# rac_cfg register map
Vendor: Texas Instruments
Peripheral module from a debugger description file (folder Keystone2).
Registers are 32-bit, read-write, no defined reset value unless marked. A register's access mark holds for its fields unless they carry their own. Offsets are as the file gives them; lines under a group give offsets from that group; [hi:lo] are bit positions; {n}, {i} and the like mark numbered series; 'fields as' and 'values as' point back to an identical list; <NAME> marks a mode.

## RAC_3_CFG
0x00 fe_pid access not given
0x04 fe_ena
  [0] enable
0x08 fe_id_depth
  [3:0] ib_depth
0x0C fe_max
  [15:0] max_cycles
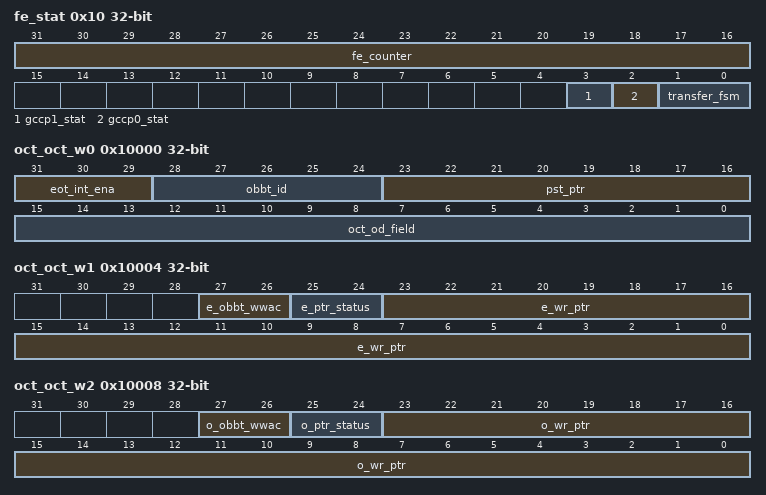
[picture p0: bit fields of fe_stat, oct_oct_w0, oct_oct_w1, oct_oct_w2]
0x10 fe_stat
  [31:16] fe_counter, [3] gccp1_stat, [2] gccp0_stat, [1:0] transfer_fsm
0x14 fe_wcfg
  [15:0] fe_wd_cfg
0x18 fe_wst
  [15:0] fe_wd_status
0x1C fe_int
  [0] int_status
0x20 fe_sw_reset
  [0] sw_reset
0x24 fe_sw_ite_start
  [0] ite_start
0x28 fe_time access not given
0x10000 oct_oct_w0 — (1 of 768, stride 16)
  [31:29] eot_int_ena, [28:24] obbt_id, [23:16] pst_ptr, [15:0] oct_od_field
0x10004 oct_oct_w1 — (1 of 768, stride 16)
  [27:26] e_obbt_wwac, [25:24] e_ptr_status, [23:0] e_wr_ptr
0x10008 oct_oct_w2 — (1 of 768, stride 16)
  [27:26] o_obbt_wwac, [25:24] o_ptr_status, [23:0] o_wr_ptr
0x13000 obbt_obbt_w0 — (1 of 32, stride 32)
  [31:0] start_ad
0x13004 obbt_obbt_w1 — (1 of 32, stride 32)
  [23:0] buff_size
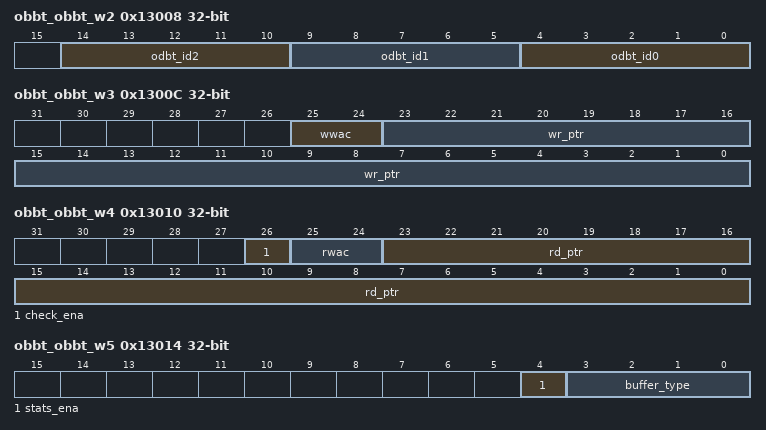
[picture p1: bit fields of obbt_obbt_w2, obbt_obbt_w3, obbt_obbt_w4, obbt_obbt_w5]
0x13008 obbt_obbt_w2 — (1 of 32, stride 32)
  [14:10] odbt_id2, [9:5] odbt_id1, [4:0] odbt_id0
0x1300C obbt_obbt_w3 — (1 of 32, stride 32)
  [25:24] wwac, [23:0] wr_ptr
0x13010 obbt_obbt_w4 — (1 of 32, stride 32)
  [26] check_ena, [25:24] rwac, [23:0] rd_ptr
0x13014 obbt_obbt_w5 — (1 of 32, stride 32)
  [4] stats_ena, [3:0] buffer_type
0x13400 odbt_odbt_w0 — (1 of 32, stride 16)
  [31:0] start_ad
0x13404 odbt_odbt_w1 — (1 of 32, stride 16)
  [15:0] buffer_size
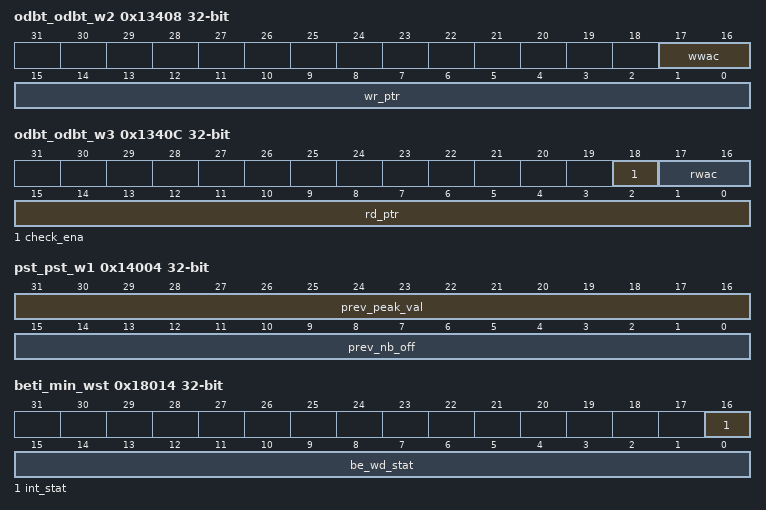
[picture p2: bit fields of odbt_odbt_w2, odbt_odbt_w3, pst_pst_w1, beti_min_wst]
0x13408 odbt_odbt_w2 — (1 of 32, stride 16)
  [17:16] wwac, [15:0] wr_ptr
0x1340C odbt_odbt_w3 — (1 of 32, stride 16)
  [18] check_ena, [17:16] rwac, [15:0] rd_ptr
0x14000 pst_pst_w0 — (1 of 256, stride 16)
  [31:0] prev_sum
0x14004 pst_pst_w1 — (1 of 256, stride 16)
  [31:16] prev_peak_val, [15:0] prev_nb_off
0x14008 pst_pst_w2 — (1 of 256, stride 16)
  [15:0] prev_peak_idx
0x18000 beti_ena
  [0] enable
0x18004 beti_stat
  [0] status
0x18010 beti_min_wcfg
  [15:0] be_wd_cfg
0x18014 beti_min_wst — (1 of 2, stride 4)
  [16] int_stat, [15:0] be_wd_stat
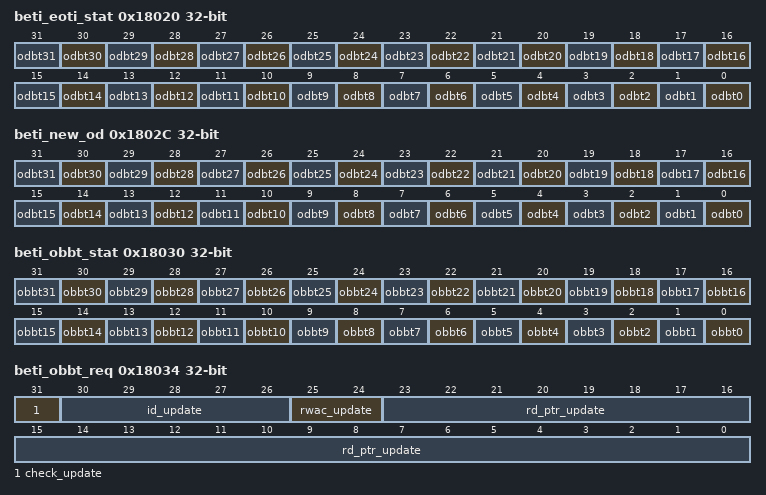
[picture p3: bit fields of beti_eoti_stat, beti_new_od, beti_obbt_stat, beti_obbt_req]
0x18020 beti_eoti_stat — (1 of 3, stride 4)
  [n] odbt{n} (n=0..31)
0x1802C beti_new_od
  [n] odbt{n} (n=0..31)
0x18030 beti_obbt_stat
  [n] obbt{n} (n=0..31)
0x18034 beti_obbt_req
  [31] check_update, [30:26] id_update, [25:24] rwac_update, [23:0] rd_ptr_update
0x18038 beti_obbt_reqs
  [0] req_status
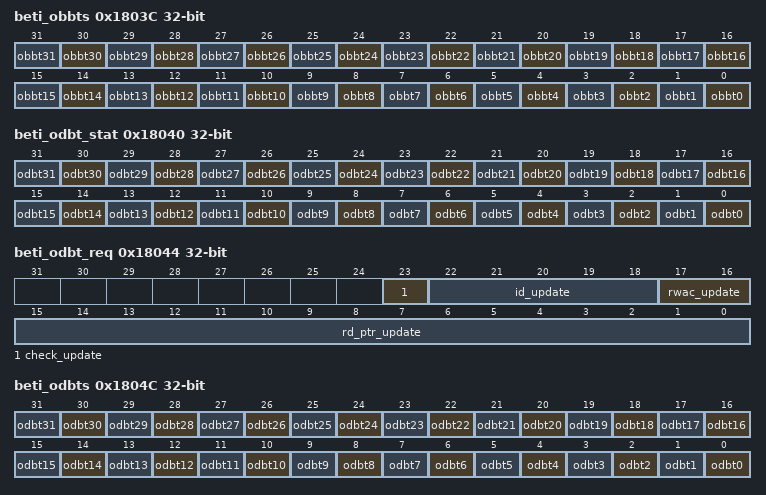
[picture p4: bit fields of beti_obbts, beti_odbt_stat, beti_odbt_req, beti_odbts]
0x1803C beti_obbts
  [n] obbt{n} (n=0..31)
0x18040 beti_odbt_stat
  [n] odbt{n} (n=0..31)
0x18044 beti_odbt_req
  [23] check_update, [22:18] id_update, [17:16] rwac_update, [15:0] rd_ptr_update
0x18048 beti_odbt_reqs
  [0] req_status
0x1804C beti_odbts
  [n] odbt{n} (n=0..31)
0x18050 beti_eoti_stat3 access not given
0x18054 beti_iq_swap
  [0] ena
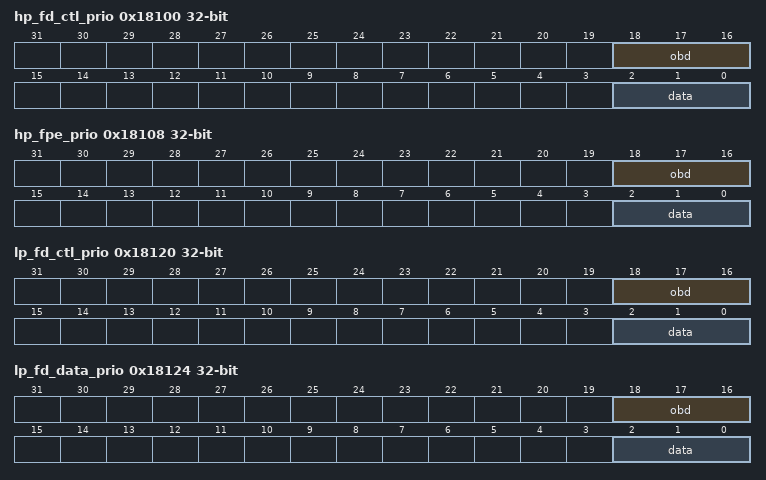
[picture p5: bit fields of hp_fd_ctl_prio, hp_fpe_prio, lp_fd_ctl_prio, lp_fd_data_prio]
0x18100 hp_fd_ctl_prio
  [18:16] obd, [2:0] data
0x18108 hp_fpe_prio
  [18:16] obd, [2:0] data
0x18120 lp_fd_ctl_prio
  [18:16] obd, [2:0] data
0x18124 lp_fd_data_prio
  [18:16] obd, [2:0] data
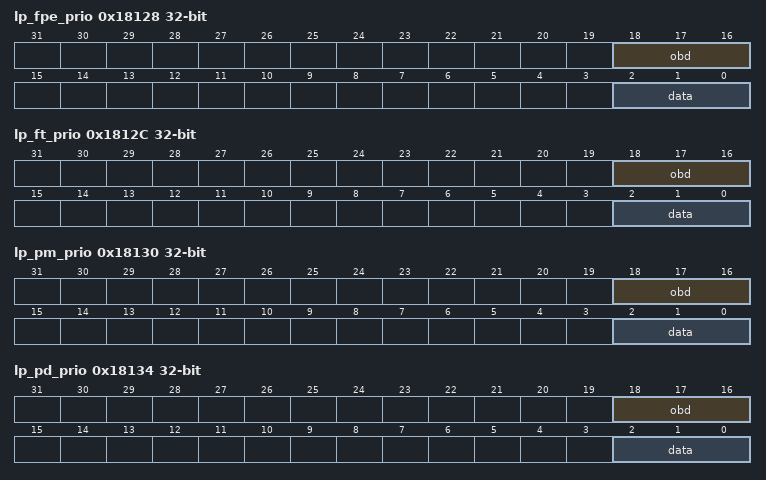
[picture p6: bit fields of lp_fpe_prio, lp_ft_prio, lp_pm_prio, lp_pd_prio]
0x18128 lp_fpe_prio
  [18:16] obd, [2:0] data
0x1812C lp_ft_prio
  [18:16] obd, [2:0] data
0x18130 lp_pm_prio
  [18:16] obd, [2:0] data
0x18134 lp_pd_prio
  [18:16] obd, [2:0] data
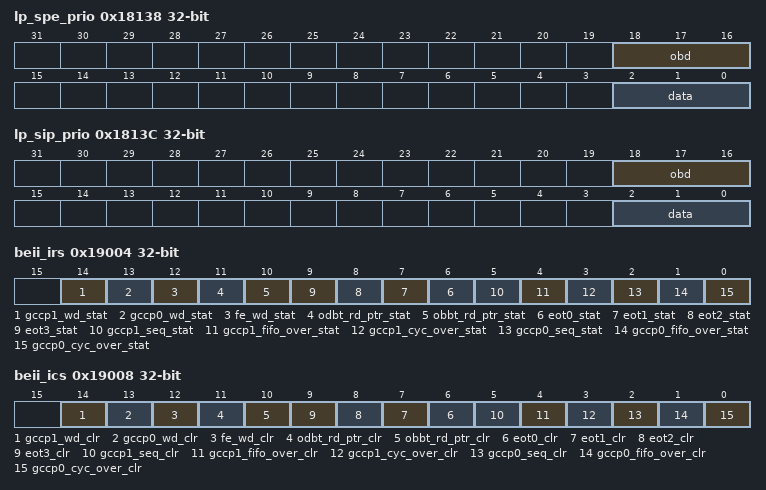
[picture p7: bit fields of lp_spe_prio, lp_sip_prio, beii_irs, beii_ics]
0x18138 lp_spe_prio
  [18:16] obd, [2:0] data
0x1813C lp_sip_prio
  [18:16] obd, [2:0] data
0x19000 beii_ena
  [0] enable
0x19004 beii_irs
  [14] gccp1_wd_stat, [13] gccp0_wd_stat, [12] fe_wd_stat, [11] odbt_rd_ptr_stat, [10] obbt_rd_ptr_stat, [n+6] eot{n}_stat (n=0..3), [5] gccp1_seq_stat, [4] gccp1_fifo_over_stat, [3] gccp1_cyc_over_stat, [2] gccp0_seq_stat, [1] gccp0_fifo_over_stat, [0] gccp0_cyc_over_stat
0x19008 beii_ics
  [14] gccp1_wd_clr, [13] gccp0_wd_clr, [12] fe_wd_clr, [11] odbt_rd_ptr_clr, [10] obbt_rd_ptr_clr, [n+6] eot{n}_clr (n=0..3), [5] gccp1_seq_clr, [4] gccp1_fifo_over_clr, [3] gccp1_cyc_over_clr, [2] gccp0_seq_clr, [1] gccp0_fifo_over_clr, [0] gccp0_cyc_over_clr
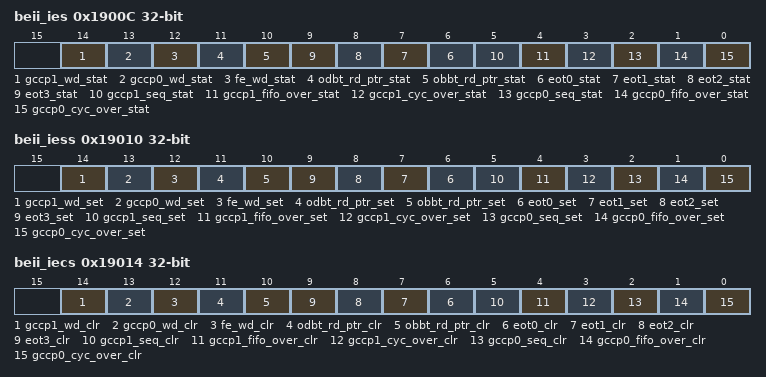
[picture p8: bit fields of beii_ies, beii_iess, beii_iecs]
0x1900C beii_ies
  fields as beii_irs
0x19010 beii_iess
  [14] gccp1_wd_set, [13] gccp0_wd_set, [12] fe_wd_set, [11] odbt_rd_ptr_set, [10] obbt_rd_ptr_set, [n+6] eot{n}_set (n=0..3), [5] gccp1_seq_set, [4] gccp1_fifo_over_set, [3] gccp1_cyc_over_set, [2] gccp0_seq_set, [1] gccp0_fifo_over_set, [0] gccp0_cyc_over_set
0x19014 beii_iecs
  fields as beii_ics
0x19018 beii_eoi access not given
0x19FFC cfg_tot
  [15:0] tot_acc_nb
0x1A000 cfg_writ
  [15:0] wr_acc_nb
0x1A004 cfg_read
  [15:0] rd_acc_nb
0x1A00C slv_tot
  [15:0] tot_acc_nb
0x1A010 slv_writ
  [15:0] wr_acc_nb
0x1A014 slv_read
  [15:0] rd_acc_nb
0x1A01C mst_tot_lp
  [15:0] tot_acc_nb
0x1A020 mst_tot_hp
  [15:0] tot_acc_nb
0x1A0FC ignore_emu
  [0] ignore_emu
